# STM32G484VET6 register map
File version: 1.0
Registers are 32-bit, access not given, reset 0x0 unless marked. A register's access mark holds for its fields unless they carry their own. Offsets are from the block's base; [hi:lo] are bit positions; {n}, {i} and the like mark numbered series.

## RCC
Base 0x40021000
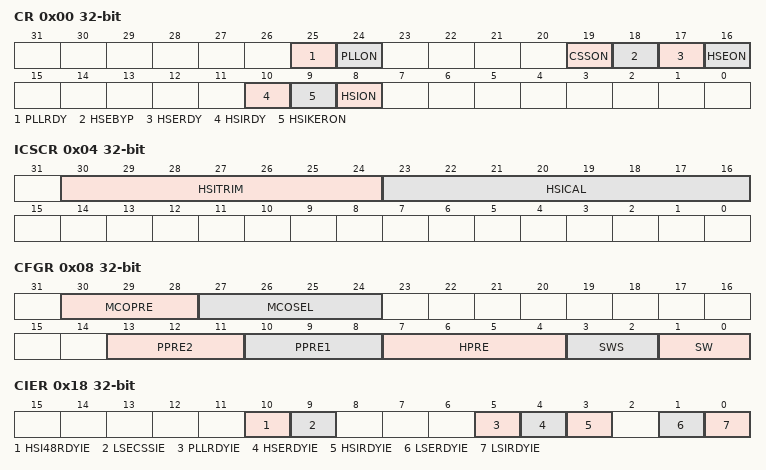
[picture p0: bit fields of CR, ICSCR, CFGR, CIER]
0x00 CR
  [25] PLLRDY, [24] PLLON, [19] CSSON, [18] HSEBYP, [17] HSERDY, [16] HSEON, [10] HSIRDY, [9] HSIKERON, [8] HSION
0x04 ICSCR
  [30:24] HSITRIM, [23:16] HSICAL
0x08 CFGR
  [30:28] MCOPRE, [27:24] MCOSEL, [13:11] PPRE2, [10:8] PPRE1, [7:4] HPRE, [3:2] SWS, [1:0] SW
0x0C PLLCFGR
  [31:27] PLLPDIV, [26:25] PLLR, [24] PLLREN, [22:21] PLLQ, [20] PLLQEN, [17] PLLP, [16] PLLPEN, [14:8] PLLN, [7:4] PLLM, [1] PLLSRC_HSI, [1:0] PLLSRC_HSE
0x18 CIER
  [10] HSI48RDYIE, [9] LSECSSIE, [5] PLLRDYIE, [4] HSERDYIE, [3] HSIRDYIE, [1] LSERDYIE, [0] LSIRDYIE
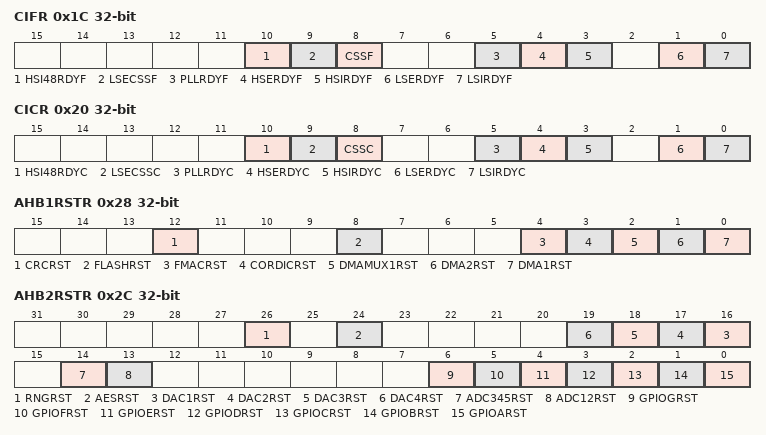
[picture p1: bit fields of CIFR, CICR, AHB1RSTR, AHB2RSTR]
0x1C CIFR
  [10] HSI48RDYF, [9] LSECSSF, [8] CSSF, [5] PLLRDYF, [4] HSERDYF, [3] HSIRDYF, [1] LSERDYF, [0] LSIRDYF
0x20 CICR
  [10] HSI48RDYC, [9] LSECSSC, [8] CSSC, [5] PLLRDYC, [4] HSERDYC, [3] HSIRDYC, [1] LSERDYC, [0] LSIRDYC
0x28 AHB1RSTR
  [12] CRCRST, [8] FLASHRST, [4] FMACRST, [3] CORDICRST, [2] DMAMUX1RST, [1] DMA2RST, [0] DMA1RST
0x2C AHB2RSTR
  [26] RNGRST, [24] AESRST, [n+15] DAC{n}RST (n=1..4), [14] ADC345RST, [13] ADC12RST, [6] GPIOGRST, [5] GPIOFRST, [4] GPIOERST, [3] GPIODRST, [2] GPIOCRST, [1] GPIOBRST, [0] GPIOARST
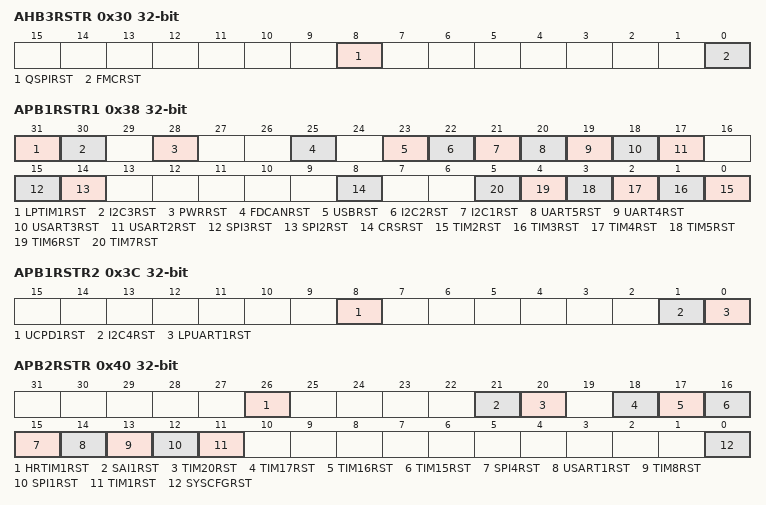
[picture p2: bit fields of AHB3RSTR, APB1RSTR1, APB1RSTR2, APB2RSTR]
0x30 AHB3RSTR
  [8] QSPIRST, [0] FMCRST
0x38 APB1RSTR1
  [31] LPTIM1RST, [30] I2C3RST, [28] PWRRST, [25] FDCANRST, [23] USBRST, [22] I2C2RST, [21] I2C1RST, [20] UART5RST, [19] UART4RST, [18] USART3RST, [17] USART2RST, [15] SPI3RST, [14] SPI2RST, [8] CRSRST, [n-2] TIM{n}RST (n=2..7)
0x3C APB1RSTR2
  [8] UCPD1RST, [1] I2C4RST, [0] LPUART1RST
0x40 APB2RSTR
  [26] HRTIM1RST, [21] SAI1RST, [20] TIM20RST, [18] TIM17RST, [17] TIM16RST, [16] TIM15RST, [15] SPI4RST, [14] USART1RST, [13] TIM8RST, [12] SPI1RST, [11] TIM1RST, [0] SYSCFGRST
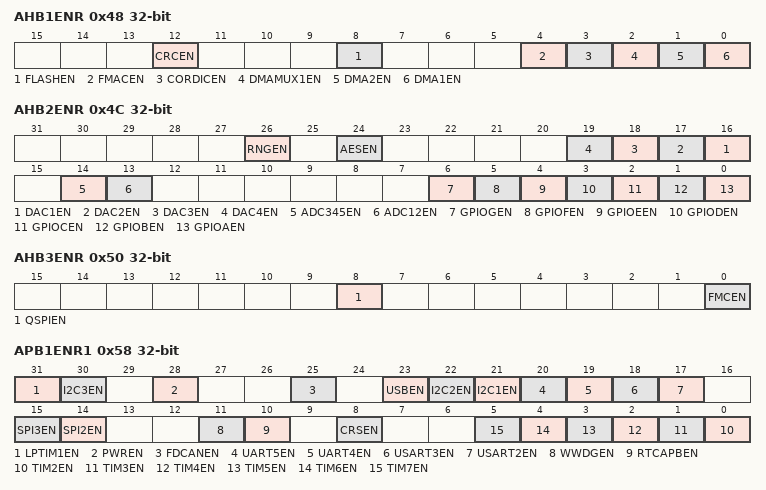
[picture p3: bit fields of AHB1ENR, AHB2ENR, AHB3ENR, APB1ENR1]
0x48 AHB1ENR
  [12] CRCEN, [8] FLASHEN, [4] FMACEN, [3] CORDICEN, [2] DMAMUX1EN, [1] DMA2EN, [0] DMA1EN
0x4C AHB2ENR
  [26] RNGEN, [24] AESEN, [n+15] DAC{n}EN (n=1..4), [14] ADC345EN, [13] ADC12EN, [6] GPIOGEN, [5] GPIOFEN, [4] GPIOEEN, [3] GPIODEN, [2] GPIOCEN, [1] GPIOBEN, [0] GPIOAEN
0x50 AHB3ENR
  [8] QSPIEN, [0] FMCEN
0x58 APB1ENR1
  [31] LPTIM1EN, [30] I2C3EN, [28] PWREN, [25] FDCANEN, [23] USBEN, [22] I2C2EN, [21] I2C1EN, [20] UART5EN, [19] UART4EN, [18] USART3EN, [17] USART2EN, [15] SPI3EN, [14] SPI2EN, [11] WWDGEN, [10] RTCAPBEN, [8] CRSEN, [n-2] TIM{n}EN (n=2..7)
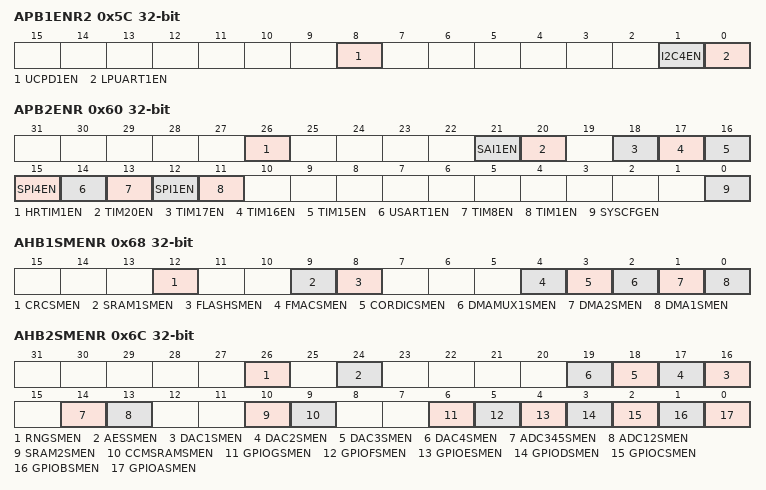
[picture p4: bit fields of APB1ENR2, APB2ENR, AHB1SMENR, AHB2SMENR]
0x5C APB1ENR2
  [8] UCPD1EN, [1] I2C4EN, [0] LPUART1EN
0x60 APB2ENR
  [26] HRTIM1EN, [21] SAI1EN, [20] TIM20EN, [18] TIM17EN, [17] TIM16EN, [16] TIM15EN, [15] SPI4EN, [14] USART1EN, [13] TIM8EN, [12] SPI1EN, [11] TIM1EN, [0] SYSCFGEN
0x68 AHB1SMENR
  [12] CRCSMEN, [9] SRAM1SMEN, [8] FLASHSMEN, [4] FMACSMEN, [3] CORDICSMEN, [2] DMAMUX1SMEN, [1] DMA2SMEN, [0] DMA1SMEN
0x6C AHB2SMENR
  [26] RNGSMEN, [24] AESSMEN, [n+15] DAC{n}SMEN (n=1..4), [14] ADC345SMEN, [13] ADC12SMEN, [10] SRAM2SMEN, [9] CCMSRAMSMEN, [6] GPIOGSMEN, [5] GPIOFSMEN, [4] GPIOESMEN, [3] GPIODSMEN, [2] GPIOCSMEN, [1] GPIOBSMEN, [0] GPIOASMEN
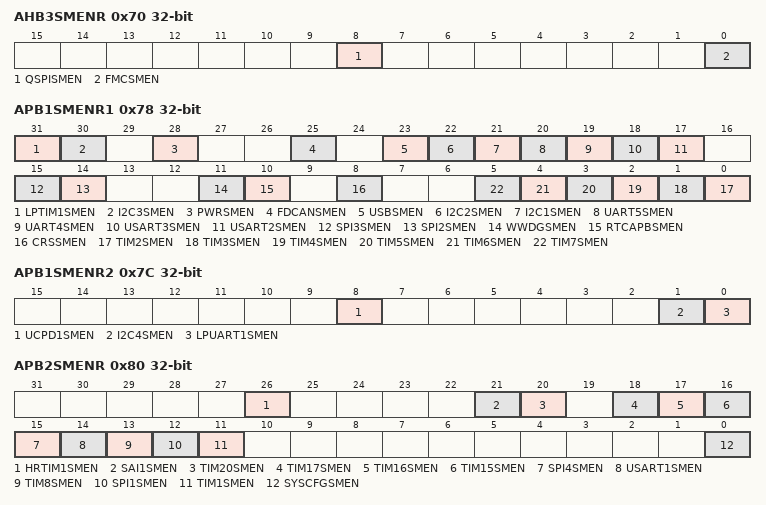
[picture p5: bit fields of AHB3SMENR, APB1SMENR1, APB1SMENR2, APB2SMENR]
0x70 AHB3SMENR
  [8] QSPISMEN, [0] FMCSMEN
0x78 APB1SMENR1
  [31] LPTIM1SMEN, [30] I2C3SMEN, [28] PWRSMEN, [25] FDCANSMEN, [23] USBSMEN, [22] I2C2SMEN, [21] I2C1SMEN, [20] UART5SMEN, [19] UART4SMEN, [18] USART3SMEN, [17] USART2SMEN, [15] SPI3SMEN, [14] SPI2SMEN, [11] WWDGSMEN, [10] RTCAPBSMEN, [8] CRSSMEN, [n-2] TIM{n}SMEN (n=2..7)
0x7C APB1SMENR2
  [8] UCPD1SMEN, [1] I2C4SMEN, [0] LPUART1SMEN
0x80 APB2SMENR
  [26] HRTIM1SMEN, [21] SAI1SMEN, [20] TIM20SMEN, [18] TIM17SMEN, [17] TIM16SMEN, [16] TIM15SMEN, [15] SPI4SMEN, [14] USART1SMEN, [13] TIM8SMEN, [12] SPI1SMEN, [11] TIM1SMEN, [0] SYSCFGSMEN
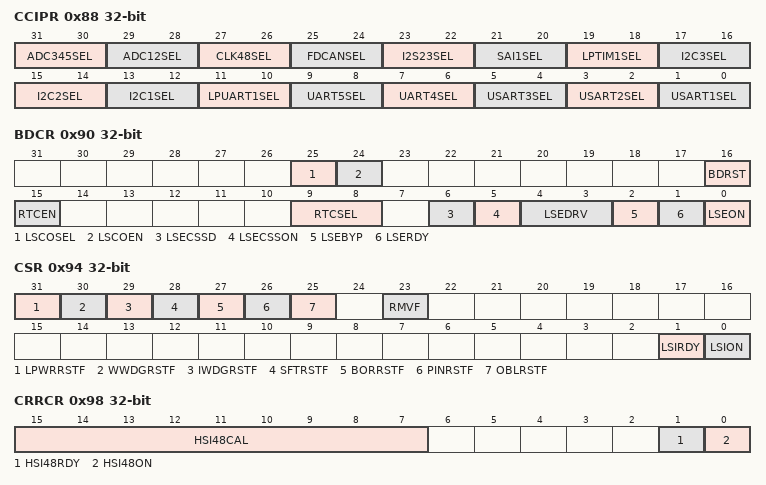
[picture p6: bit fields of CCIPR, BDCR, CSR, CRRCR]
0x88 CCIPR
  [31:30] ADC345SEL, [29:28] ADC12SEL, [27:26] CLK48SEL, [25:24] FDCANSEL, [23:22] I2S23SEL, [21:20] SAI1SEL, [19:18] LPTIM1SEL, [17:16] I2C3SEL, [15:14] I2C2SEL, [13:12] I2C1SEL, [11:10] LPUART1SEL, [9:8] UART5SEL, [7:6] UART4SEL, [5:4] USART3SEL, [3:2] USART2SEL, [1:0] USART1SEL
0x90 BDCR
  [25] LSCOSEL, [24] LSCOEN, [16] BDRST, [15] RTCEN, [9:8] RTCSEL, [6] LSECSSD, [5] LSECSSON, [4:3] LSEDRV, [2] LSEBYP, [1] LSERDY, [0] LSEON
0x94 CSR
  [31] LPWRRSTF, [30] WWDGRSTF, [29] IWDGRSTF, [28] SFTRSTF, [27] BORRSTF, [26] PINRSTF, [25] OBLRSTF, [23] RMVF, [1] LSIRDY, [0] LSION
0x98 CRRCR
  [15:7] HSI48CAL, [1] HSI48RDY, [0] HSI48ON
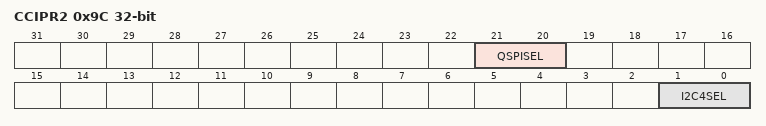
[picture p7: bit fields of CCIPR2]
0x9C CCIPR2
  [21:20] QSPISEL, [1:0] I2C4SEL
